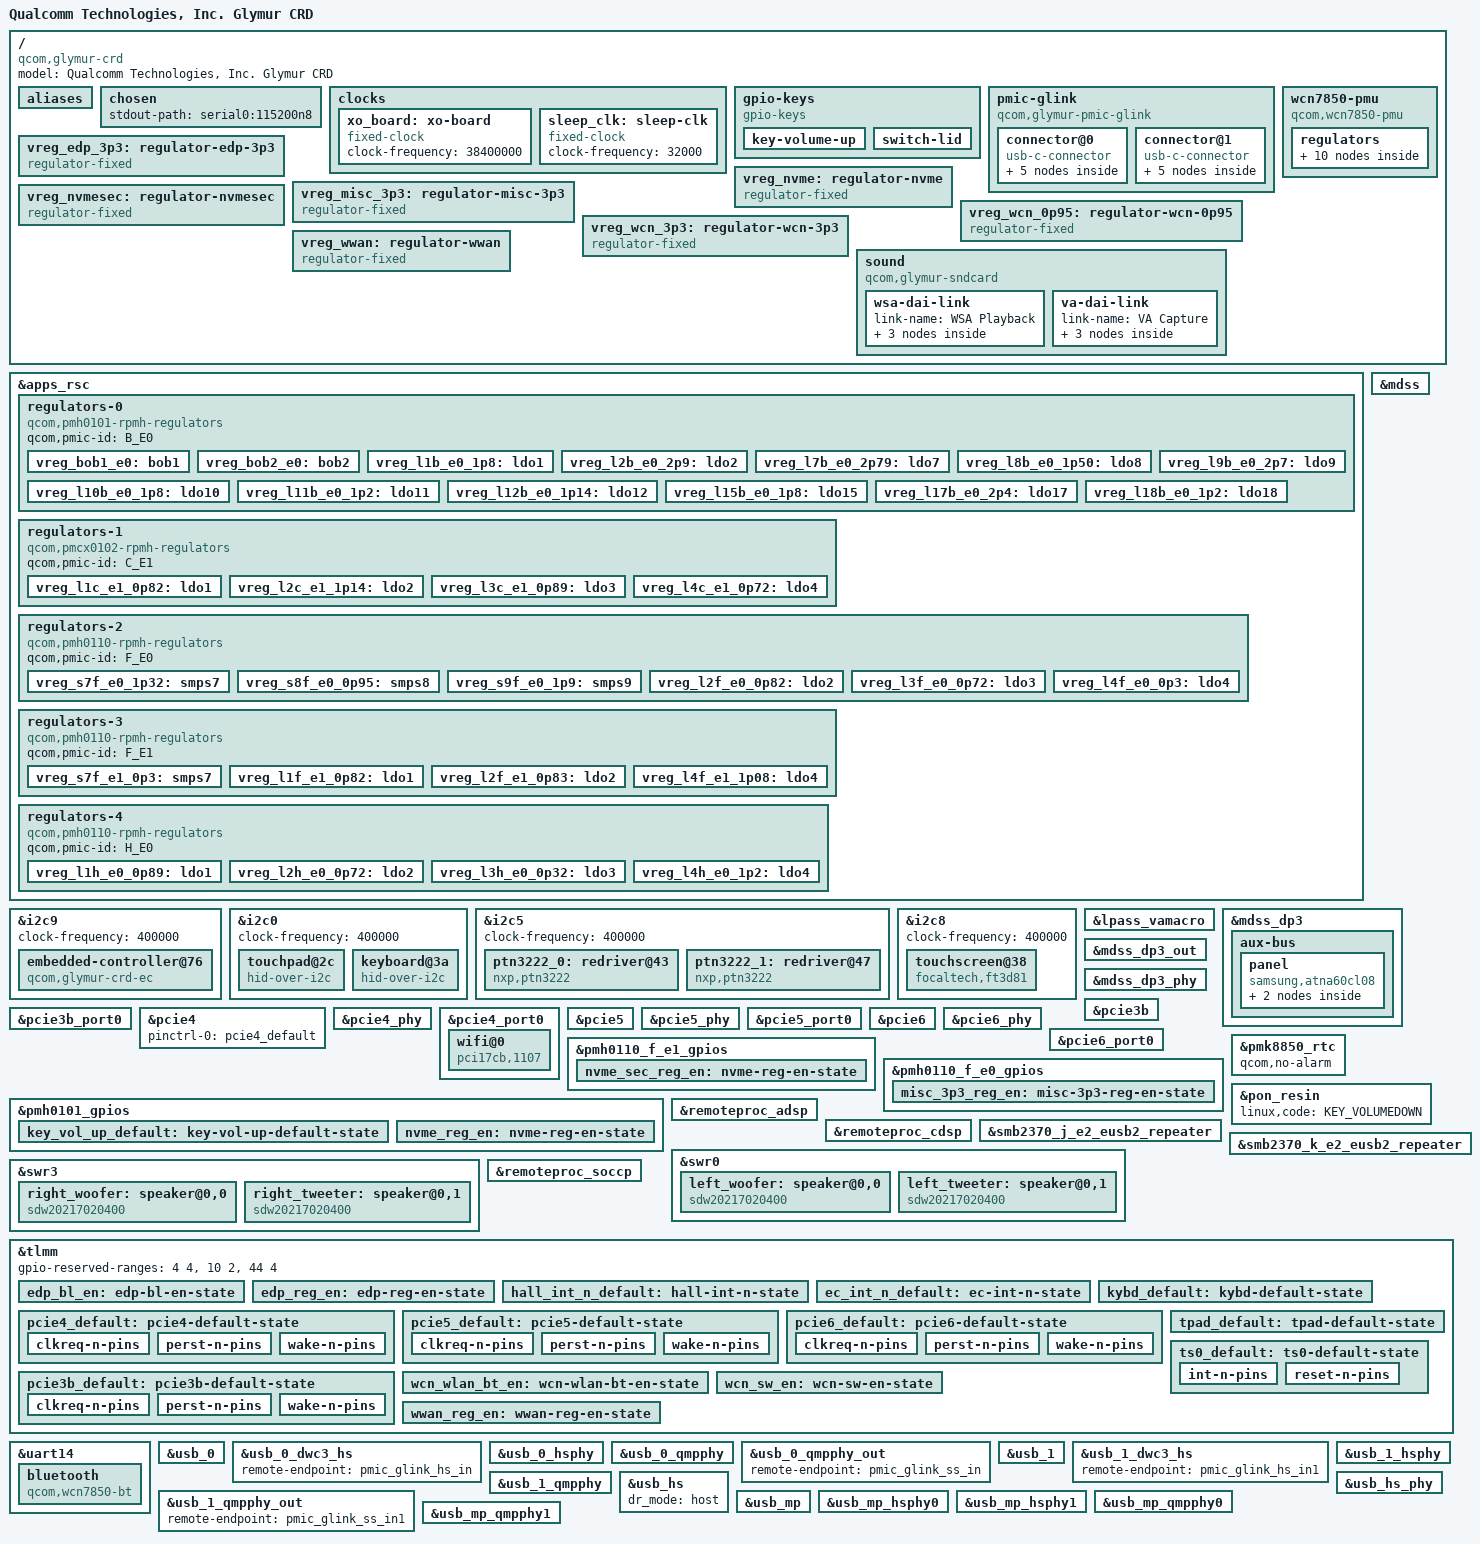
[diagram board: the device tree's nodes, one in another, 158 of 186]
// SPDX-License-Identifier: BSD-3-Clause
/*
 * Copyright (c) Qualcomm Technologies, Inc. and/or its subsidiaries.
 */

#include "pmcx0102.dtsi"        /* SPMI0: SID-2/3 SPMI1: SID-2/3 */
#include "pmh0101.dtsi"         /* SPMI0: SID-1                  */
#include "pmh0110-glymur.dtsi"  /* SPMI0: SID-5/7 SPMI1: SID-5   */
#include "pmh0104-glymur.dtsi"  /* SPMI0: SID-8/9 SPMI1: SID-11  */
#include "pmk8850.dtsi"         /* SPMI0: SID-0                  */
#include "smb2370.dtsi"         /* SPMI2: SID-9/10/11            */

#include <dt-bindings/input/gpio-keys.h>
#include <dt-bindings/pinctrl/qcom,pmic-gpio.h>

/ {
	model = "Qualcomm Technologies, Inc. Glymur CRD";
	compatible = "qcom,glymur-crd", "qcom,glymur";

	aliases {
		serial0 = &uart21;
		serial1 = &uart14;
		i2c0 = &i2c0;
		i2c1 = &i2c4;
		i2c2 = &i2c5;
		i2c3 = &i2c9;
		spi0 = &spi18;
	};

	chosen {
		stdout-path = "serial0:115200n8";
	};

	clocks {
		xo_board: xo-board {
			compatible = "fixed-clock";
			clock-frequency = <38400000>;
			#clock-cells = <0>;
		};

		sleep_clk: sleep-clk {
			compatible = "fixed-clock";
			clock-frequency = <32000>;
			#clock-cells = <0>;
		};
	};

	gpio-keys {
		compatible = "gpio-keys";

		pinctrl-0 = <&key_vol_up_default>, <&hall_int_n_default>;
		pinctrl-names = "default";

		key-volume-up {
			label = "Volume Up";
			linux,code = <KEY_VOLUMEUP>;
			gpios = <&pmh0101_gpios 6 GPIO_ACTIVE_LOW>;
			debounce-interval = <15>;
			linux,can-disable;
			wakeup-source;
		};

		switch-lid {
			label = "lid";
			gpios = <&tlmm 92 GPIO_ACTIVE_LOW>;
			linux,input-type = <EV_SW>;
			linux,code = <SW_LID>;
			wakeup-source;
			wakeup-event-action = <EV_ACT_DEASSERTED>;
		};
	};

	pmic-glink {
		compatible = "qcom,glymur-pmic-glink",
			     "qcom,pmic-glink";
		#address-cells = <1>;
		#size-cells = <0>;

		connector@0 {
			compatible = "usb-c-connector";
			reg = <0>;
			power-role = "dual";
			data-role = "dual";

			ports {
				#address-cells = <1>;
				#size-cells = <0>;

				port@0 {
					reg = <0>;

					pmic_glink_hs_in: endpoint {
						remote-endpoint = <&usb_0_dwc3_hs>;
					};
				};

				port@1 {
					reg = <1>;

					pmic_glink_ss_in: endpoint {
						remote-endpoint = <&usb_0_qmpphy_out>;
					};
				};
			};
		};

		connector@1 {
			compatible = "usb-c-connector";
			reg = <1>;
			power-role = "dual";
			data-role = "dual";

			ports {
				#address-cells = <1>;
				#size-cells = <0>;

				port@0 {
					reg = <0>;

					pmic_glink_hs_in1: endpoint {
						remote-endpoint = <&usb_1_dwc3_hs>;
					};
				};

				port@1 {
					reg = <1>;

					pmic_glink_ss_in1: endpoint {
						remote-endpoint = <&usb_1_qmpphy_out>;
					};
				};
			};
		};
	};

	vreg_edp_3p3: regulator-edp-3p3 {
		compatible = "regulator-fixed";

		regulator-name = "VREG_EDP_3P3";
		regulator-min-microvolt = <3300000>;
		regulator-max-microvolt = <3300000>;

		gpio = <&tlmm 70 GPIO_ACTIVE_HIGH>;
		enable-active-high;

		pinctrl-0 = <&edp_reg_en>;
		pinctrl-names = "default";

		regulator-boot-on;
	};

	vreg_misc_3p3: regulator-misc-3p3 {
		compatible = "regulator-fixed";

		regulator-name = "VREG_MISC_3P3";
		regulator-min-microvolt = <3300000>;
		regulator-max-microvolt = <3300000>;

		gpio = <&pmh0110_f_e0_gpios 6 GPIO_ACTIVE_HIGH>;
		enable-active-high;

		pinctrl-0 = <&misc_3p3_reg_en>;
		pinctrl-names = "default";

		regulator-boot-on;
	};

	vreg_nvme: regulator-nvme {
		compatible = "regulator-fixed";

		regulator-name = "VREG_NVME_3P3";
		regulator-min-microvolt = <3300000>;
		regulator-max-microvolt = <3300000>;

		gpio = <&pmh0101_gpios 14 GPIO_ACTIVE_HIGH>;
		enable-active-high;

		pinctrl-0 = <&nvme_reg_en>;
		pinctrl-names = "default";

		regulator-boot-on;
	};

	vreg_nvmesec: regulator-nvmesec {
		compatible = "regulator-fixed";

		regulator-name = "VREG_NVME_SEC_3P3";
		regulator-min-microvolt = <3300000>;
		regulator-max-microvolt = <3300000>;

		gpio = <&pmh0110_f_e1_gpios 14 GPIO_ACTIVE_HIGH>;
		enable-active-high;

		pinctrl-0 = <&nvme_sec_reg_en>;
		pinctrl-names = "default";

		regulator-boot-on;
	};

	vreg_wcn_0p95: regulator-wcn-0p95 {
		compatible = "regulator-fixed";

		regulator-name = "VREG_WCN_0P95";
		regulator-min-microvolt = <950000>;
		regulator-max-microvolt = <950000>;

		vin-supply = <&vreg_wcn_3p3>;
	};

	vreg_wcn_3p3: regulator-wcn-3p3 {
		compatible = "regulator-fixed";

		regulator-name = "VREG_WCN_3P3";
		regulator-min-microvolt = <3300000>;
		regulator-max-microvolt = <3300000>;

		gpio = <&tlmm 94 GPIO_ACTIVE_HIGH>;
		enable-active-high;

		pinctrl-0 = <&wcn_sw_en>;
		pinctrl-names = "default";

		regulator-boot-on;
	};

	vreg_wwan: regulator-wwan {
		compatible = "regulator-fixed";

		regulator-name = "VREG_WWAN_3P3";
		regulator-min-microvolt = <3300000>;
		regulator-max-microvolt = <3300000>;

		gpio = <&tlmm 246 GPIO_ACTIVE_HIGH>;
		enable-active-high;

		pinctrl-0 = <&wwan_reg_en>;
		pinctrl-names = "default";
	};

	sound {
		compatible = "qcom,glymur-sndcard";
		model = "GLYMUR-CRD";
		audio-routing = "WooferLeft IN", "WSA WSA_SPK1 OUT",
				"TweeterLeft IN", "WSA WSA_SPK2 OUT",
				"WooferRight IN", "WSA2 WSA_SPK1 OUT",
				"TweeterRight IN", "WSA2 WSA_SPK2 OUT",
				"VA DMIC0", "vdd-micb",
				"VA DMIC1", "vdd-micb",
				"VA DMIC2", "vdd-micb",
				"VA DMIC3", "vdd-micb";

		wsa-dai-link {
			link-name = "WSA Playback";

			cpu {
				sound-dai = <&q6apmbedai WSA_CODEC_DMA_RX_0>;
			};

			codec {
				sound-dai = <&left_woofer>, <&left_tweeter>,
					    <&swr0 0>, <&lpass_wsamacro 0>,
					    <&right_woofer>, <&right_tweeter>,
					    <&swr3 0>, <&lpass_wsa2macro 0>;
			};

			platform {
				sound-dai = <&q6apm>;
			};
		};

		va-dai-link {
			link-name = "VA Capture";

			cpu {
				sound-dai = <&q6apmbedai VA_CODEC_DMA_TX_0>;
			};

			codec {
				sound-dai = <&lpass_vamacro 0>;
			};

			platform {
				sound-dai = <&q6apm>;
			};
		};
	};

	wcn7850-pmu {
		compatible = "qcom,wcn7850-pmu";

		vdd-supply = <&vreg_wcn_0p95>;
		vddio-supply = <&vreg_l15b_e0_1p8>;
		vddaon-supply = <&vreg_l15b_e0_1p8>;
		vdddig-supply = <&vreg_l15b_e0_1p8>;
		vddrfa1p2-supply = <&vreg_l15b_e0_1p8>;
		vddrfa1p8-supply = <&vreg_l15b_e0_1p8>;

		wlan-enable-gpios = <&tlmm 117 GPIO_ACTIVE_HIGH>;
		bt-enable-gpios = <&tlmm 116 GPIO_ACTIVE_HIGH>;

		pinctrl-0 = <&wcn_wlan_bt_en>;
		pinctrl-names = "default";

		regulators {
			vreg_pmu_rfa_cmn: ldo0 {
				regulator-name = "vreg_pmu_rfa_cmn";
			};

			vreg_pmu_aon_0p59: ldo1 {
				regulator-name = "vreg_pmu_aon_0p59";
			};

			vreg_pmu_wlcx_0p8: ldo2 {
				regulator-name = "vreg_pmu_wlcx_0p8";
			};

			vreg_pmu_wlmx_0p85: ldo3 {
				regulator-name = "vreg_pmu_wlmx_0p85";
			};

			vreg_pmu_btcmx_0p85: ldo4 {
				regulator-name = "vreg_pmu_btcmx_0p85";
			};

			vreg_pmu_rfa_0p8: ldo5 {
				regulator-name = "vreg_pmu_rfa_0p8";
			};

			vreg_pmu_rfa_1p2: ldo6 {
				regulator-name = "vreg_pmu_rfa_1p2";
			};

			vreg_pmu_rfa_1p8: ldo7 {
				regulator-name = "vreg_pmu_rfa_1p8";
			};

			vreg_pmu_pcie_0p9: ldo8 {
				regulator-name = "vreg_pmu_pcie_0p9";
			};

			vreg_pmu_pcie_1p8: ldo9 {
				regulator-name = "vreg_pmu_pcie_1p8";
			};
		};
	};
};

&apps_rsc {
	regulators-0 {
		compatible = "qcom,pmh0101-rpmh-regulators";
		qcom,pmic-id = "B_E0";

		vreg_bob1_e0: bob1 {
			regulator-name = "vreg_bob1_e0";
			regulator-min-microvolt = <2200000>;
			regulator-max-microvolt = <4224000>;
			regulator-initial-mode = <RPMH_REGULATOR_MODE_AUTO>;
		};

		vreg_bob2_e0: bob2 {
			regulator-name = "vreg_bob2_e0";
			regulator-min-microvolt = <2540000>;
			regulator-max-microvolt = <3600000>;
			regulator-initial-mode = <RPMH_REGULATOR_MODE_AUTO>;
		};

		vreg_l1b_e0_1p8: ldo1 {
			regulator-name = "vreg_l1b_e0_1p8";
			regulator-min-microvolt = <1800000>;
			regulator-max-microvolt = <1800000>;
			regulator-initial-mode = <RPMH_REGULATOR_MODE_HPM>;
		};

		vreg_l2b_e0_2p9: ldo2 {
			regulator-name = "vreg_l2b_e0_2p9";
			regulator-min-microvolt = <2904000>;
			regulator-max-microvolt = <2904000>;
			regulator-initial-mode = <RPMH_REGULATOR_MODE_HPM>;
		};

		vreg_l7b_e0_2p79: ldo7 {
			regulator-name = "vreg_l7b_e0_2p79";
			regulator-min-microvolt = <2790000>;
			regulator-max-microvolt = <2792000>;
			regulator-initial-mode = <RPMH_REGULATOR_MODE_HPM>;
		};

		vreg_l8b_e0_1p50: ldo8 {
			regulator-name = "vreg_l8b_e0_1p50";
			regulator-min-microvolt = <1504000>;
			regulator-max-microvolt = <1504000>;
			regulator-initial-mode = <RPMH_REGULATOR_MODE_HPM>;
		};

		vreg_l9b_e0_2p7: ldo9 {
			regulator-name = "vreg_l9b_e0_2p7";
			regulator-min-microvolt = <2704000>;
			regulator-max-microvolt = <2704000>;
			regulator-initial-mode = <RPMH_REGULATOR_MODE_HPM>;
		};

		vreg_l10b_e0_1p8: ldo10 {
			regulator-name = "vreg_l10b_e0_1p8";
			regulator-min-microvolt = <1800000>;
			regulator-max-microvolt = <1800000>;
			regulator-initial-mode = <RPMH_REGULATOR_MODE_HPM>;
		};

		vreg_l11b_e0_1p2: ldo11 {
			regulator-name = "vreg_l11b_e0_1p2";
			regulator-min-microvolt = <1200000>;
			regulator-max-microvolt = <1200000>;
			regulator-initial-mode = <RPMH_REGULATOR_MODE_HPM>;
		};

		vreg_l12b_e0_1p14: ldo12 {
			regulator-name = "vreg_l12b_e0_1p14";
			regulator-min-microvolt = <1144000>;
			regulator-max-microvolt = <1144000>;
			regulator-initial-mode = <RPMH_REGULATOR_MODE_HPM>;
		};

		vreg_l15b_e0_1p8: ldo15 {
			regulator-name = "vreg_l15b_e0_1p8";
			regulator-min-microvolt = <1800000>;
			regulator-max-microvolt = <1800000>;
			regulator-initial-mode = <RPMH_REGULATOR_MODE_HPM>;
		};

		vreg_l17b_e0_2p4: ldo17 {
			regulator-name = "vreg_l17b_e0_2p4";
			regulator-min-microvolt = <2400000>;
			regulator-max-microvolt = <2700000>;
			regulator-initial-mode = <RPMH_REGULATOR_MODE_HPM>;
		};

		vreg_l18b_e0_1p2: ldo18 {
			regulator-name = "vreg_l18b_e0_1p2";
			regulator-min-microvolt = <1200000>;
			regulator-max-microvolt = <1200000>;
			regulator-initial-mode = <RPMH_REGULATOR_MODE_HPM>;
		};
	};

	regulators-1 {
		compatible = "qcom,pmcx0102-rpmh-regulators";
		qcom,pmic-id = "C_E1";

		vreg_l1c_e1_0p82: ldo1 {
			regulator-name = "vreg_l1c_e1_0p82";
			regulator-min-microvolt = <832000>;
			regulator-max-microvolt = <832000>;
			regulator-initial-mode = <RPMH_REGULATOR_MODE_HPM>;
		};

		vreg_l2c_e1_1p14: ldo2 {
			regulator-name = "vreg_l2c_e1_1p14";
			regulator-min-microvolt = <1144000>;
			regulator-max-microvolt = <1144000>;
			regulator-initial-mode = <RPMH_REGULATOR_MODE_HPM>;
		};

		vreg_l3c_e1_0p89: ldo3 {
			regulator-name = "vreg_l3c_e1_0p89";
			regulator-min-microvolt = <890000>;
			regulator-max-microvolt = <980000>;
			regulator-initial-mode = <RPMH_REGULATOR_MODE_HPM>;
		};

		vreg_l4c_e1_0p72: ldo4 {
			regulator-name = "vreg_l4c_e1_0p72";
			regulator-min-microvolt = <720000>;
			regulator-max-microvolt = <720000>;
			regulator-initial-mode = <RPMH_REGULATOR_MODE_HPM>;
		};
	};

	regulators-2 {
		compatible = "qcom,pmh0110-rpmh-regulators";
		qcom,pmic-id = "F_E0";

		vreg_s7f_e0_1p32: smps7 {
			regulator-name = "vreg_s7f_e0_1p32";
			regulator-min-microvolt = <1320000>;
			regulator-max-microvolt = <1352000>;
			regulator-initial-mode = <RPMH_REGULATOR_MODE_HPM>;
		};

		vreg_s8f_e0_0p95: smps8 {
			regulator-name = "vreg_s8f_e0_0p95";
			regulator-min-microvolt = <952000>;
			regulator-max-microvolt = <1200000>;
			regulator-initial-mode = <RPMH_REGULATOR_MODE_HPM>;
		};

		vreg_s9f_e0_1p9: smps9 {
			regulator-name = "vreg_s9f_e0_1p9";
			regulator-min-microvolt = <1900000>;
			regulator-max-microvolt = <2000000>;
			regulator-initial-mode = <RPMH_REGULATOR_MODE_HPM>;
		};

		vreg_l2f_e0_0p82: ldo2 {
			regulator-name = "vreg_l2f_e0_0p82";
			regulator-min-microvolt = <832000>;
			regulator-max-microvolt = <832000>;
			regulator-initial-mode = <RPMH_REGULATOR_MODE_HPM>;
		};

		vreg_l3f_e0_0p72: ldo3 {
			regulator-name = "vreg_l3f_e0_0p72";
			regulator-min-microvolt = <720000>;
			regulator-max-microvolt = <720000>;
			regulator-initial-mode = <RPMH_REGULATOR_MODE_HPM>;
		};

		vreg_l4f_e0_0p3: ldo4 {
			regulator-name = "vreg_l4f_e0_0p3";
			regulator-min-microvolt = <1080000>;
			regulator-max-microvolt = <1200000>;
			regulator-initial-mode = <RPMH_REGULATOR_MODE_HPM>;
		};
	};

	regulators-3 {
		compatible = "qcom,pmh0110-rpmh-regulators";
		qcom,pmic-id = "F_E1";

		vreg_s7f_e1_0p3: smps7 {
			regulator-name = "vreg_s7f_e1_0p3";
			regulator-min-microvolt = <300000>;
			regulator-max-microvolt = <1200000>;
			regulator-initial-mode = <RPMH_REGULATOR_MODE_HPM>;
		};

		vreg_l1f_e1_0p82: ldo1 {
			regulator-name = "vreg_l1f_e1_0p82";
			regulator-min-microvolt = <832000>;
			regulator-max-microvolt = <832000>;
			regulator-initial-mode = <RPMH_REGULATOR_MODE_HPM>;
		};

		vreg_l2f_e1_0p83: ldo2 {
			regulator-name = "vreg_l2f_e1_0p83";
			regulator-min-microvolt = <832000>;
			regulator-max-microvolt = <832000>;
			regulator-initial-mode = <RPMH_REGULATOR_MODE_HPM>;
		};

		vreg_l4f_e1_1p08: ldo4 {
			regulator-name = "vreg_l4f_e1_1p08";
			regulator-min-microvolt = <1080000>;
			regulator-max-microvolt = <1320000>;
			regulator-initial-mode = <RPMH_REGULATOR_MODE_HPM>;
		};
	};

	regulators-4 {
		compatible = "qcom,pmh0110-rpmh-regulators";
		qcom,pmic-id = "H_E0";

		vreg_l1h_e0_0p89: ldo1 {
			regulator-name = "vreg_l1h_e0_0p89";
			regulator-min-microvolt = <832000>;
			regulator-max-microvolt = <832000>;
			regulator-initial-mode = <RPMH_REGULATOR_MODE_HPM>;
		};

		vreg_l2h_e0_0p72: ldo2 {
			regulator-name = "vreg_l2h_e0_0p72";
			regulator-min-microvolt = <832000>;
			regulator-max-microvolt = <832000>;
			regulator-initial-mode = <RPMH_REGULATOR_MODE_HPM>;
		};

		vreg_l3h_e0_0p32: ldo3 {
			regulator-name = "vreg_l3h_e0_0p32";
			regulator-min-microvolt = <320000>;
			regulator-max-microvolt = <2000000>;
			regulator-initial-mode = <RPMH_REGULATOR_MODE_HPM>;
		};

		vreg_l4h_e0_1p2: ldo4 {
			regulator-name = "vreg_l4h_e0_1p2";
			regulator-min-microvolt = <1080000>;
			regulator-max-microvolt = <1320000>;
			regulator-initial-mode = <RPMH_REGULATOR_MODE_HPM>;
		};
	};
};

&i2c9 {
	clock-frequency = <400000>;

	status = "okay";

	embedded-controller@76 {
		compatible = "qcom,glymur-crd-ec", "qcom,hamoa-crd-ec";
		reg = <0x76>;

		interrupts-extended = <&tlmm 66 IRQ_TYPE_EDGE_FALLING>;

		pinctrl-0 = <&ec_int_n_default>;
		pinctrl-names = "default";
	};
};

&i2c0 {
	clock-frequency = <400000>;

	status = "okay";

	touchpad@2c {
		compatible = "hid-over-i2c";
		reg = <0x2c>;

		hid-descr-addr = <0x20>;
		interrupts-extended = <&tlmm 3 IRQ_TYPE_LEVEL_LOW>;

		vdd-supply = <&vreg_misc_3p3>;
		vddl-supply = <&vreg_l15b_e0_1p8>;

		pinctrl-0 = <&tpad_default>;
		pinctrl-names = "default";

		wakeup-source;
	};

	keyboard@3a {
		compatible = "hid-over-i2c";
		reg = <0x3a>;

		hid-descr-addr = <0x1>;
		interrupts-extended = <&tlmm 67 IRQ_TYPE_LEVEL_LOW>;

		vdd-supply = <&vreg_misc_3p3>;
		vddl-supply = <&vreg_l15b_e0_1p8>;

		pinctrl-0 = <&kybd_default>;
		pinctrl-names = "default";

		wakeup-source;
	};
};

&i2c5 {
	clock-frequency = <400000>;

	status = "okay";

	ptn3222_0: redriver@43 {
		compatible = "nxp,ptn3222";
		reg = <0x43>;

		reset-gpios = <&tlmm 8 GPIO_ACTIVE_LOW>;

		vdd3v3-supply = <&vreg_l8b_e0_1p50>;
		vdd1v8-supply = <&vreg_l15b_e0_1p8>;

		#phy-cells = <0>;
	};

	ptn3222_1: redriver@47 {
		compatible = "nxp,ptn3222";
		reg = <0x47>;

		reset-gpios = <&tlmm 9 GPIO_ACTIVE_LOW>;

		vdd3v3-supply = <&vreg_l8b_e0_1p50>;
		vdd1v8-supply = <&vreg_l15b_e0_1p8>;

		#phy-cells = <0>;
	};
};

&i2c8 {
	clock-frequency = <400000>;

	status = "okay";

	touchscreen@38 {
		compatible = "focaltech,ft3d81", "focaltech,ft8112";
		reg = <0x38>;

		interrupts-extended = <&tlmm 51 IRQ_TYPE_LEVEL_LOW>;

		vcc33-supply = <&vreg_misc_3p3>;
		vccio-supply = <&vreg_l15b_e0_1p8>;

		reset-gpios = <&tlmm 48 GPIO_ACTIVE_LOW>;

		pinctrl-0 = <&ts0_default>;
		pinctrl-names = "default";
	};
};

&lpass_vamacro {
	pinctrl-0 = <&dmic01_default>, <&dmic23_default>;
	pinctrl-names = "default";
	qcom,dmic-sample-rate = <4800000>;
	vdd-micb-supply = <&vreg_l1b_e0_1p8>;
};

&mdss {
	status = "okay";
};

&mdss_dp3 {
	/delete-property/ #sound-dai-cells;

	status = "okay";

	aux-bus {
		panel {
			compatible = "samsung,atna60cl08", "samsung,atna33xc20";
			enable-gpios = <&tlmm 18 GPIO_ACTIVE_HIGH>;
			power-supply = <&vreg_edp_3p3>;

			pinctrl-0 = <&edp_bl_en>;
			pinctrl-names = "default";

			port {
				edp_panel_in: endpoint {
					remote-endpoint = <&mdss_dp3_out>;
				};
			};
		};
	};
};

&mdss_dp3_out {
	data-lanes = <0 1 2 3>;
	link-frequencies = /bits/ 64 <1620000000 2700000000 5400000000 8100000000>;

	remote-endpoint = <&edp_panel_in>;
};

&mdss_dp3_phy {
	vdda-phy-supply = <&vreg_l2f_e1_0p83>;
	vdda-pll-supply = <&vreg_l4f_e1_1p08>;

	status = "okay";
};

&pcie3b {
	vddpe-3v3-supply = <&vreg_nvmesec>;

	pinctrl-0 = <&pcie3b_default>;
	pinctrl-names = "default";
};

&pcie3b_port0 {
	reset-gpios = <&tlmm 155 GPIO_ACTIVE_LOW>;
	wake-gpios = <&tlmm 157 GPIO_ACTIVE_LOW>;
};

&pcie4 {
	pinctrl-0 = <&pcie4_default>;
	pinctrl-names = "default";

	status = "okay";
};

&pcie4_phy {
	vdda-phy-supply = <&vreg_l1c_e1_0p82>;
	vdda-pll-supply = <&vreg_l4f_e1_1p08>;

	status = "okay";
};

&pcie4_port0 {
	reset-gpios = <&tlmm 146 GPIO_ACTIVE_LOW>;
	wake-gpios = <&tlmm 148 GPIO_ACTIVE_LOW>;

	wifi@0 {
		compatible = "pci17cb,1107";
		reg = <0x10000 0x0 0x0 0x0 0x0>;

		vddaon-supply = <&vreg_pmu_aon_0p59>;
		vddwlcx-supply = <&vreg_pmu_wlcx_0p8>;
		vddwlmx-supply = <&vreg_pmu_wlmx_0p85>;
		vddrfacmn-supply = <&vreg_pmu_rfa_cmn>;
		vddrfa0p8-supply = <&vreg_pmu_rfa_0p8>;
		vddrfa1p2-supply = <&vreg_pmu_rfa_1p2>;
		vddrfa1p8-supply = <&vreg_pmu_rfa_1p8>;
		vddpcie0p9-supply = <&vreg_pmu_pcie_0p9>;
		vddpcie1p8-supply = <&vreg_pmu_pcie_1p8>;
	};
};

&pcie5 {
	vddpe-3v3-supply = <&vreg_nvme>;

	pinctrl-0 = <&pcie5_default>;
	pinctrl-names = "default";

	status = "okay";
};

&pcie5_phy {
	vdda-phy-supply = <&vreg_l2f_e0_0p82>;
	vdda-pll-supply = <&vreg_l4h_e0_1p2>;

	status = "okay";
};

&pcie5_port0 {
	reset-gpios = <&tlmm 152 GPIO_ACTIVE_LOW>;
	wake-gpios = <&tlmm 154 GPIO_ACTIVE_LOW>;
};

&pcie6 {
	vddpe-3v3-supply = <&vreg_wwan>;

	pinctrl-0 = <&pcie6_default>;
	pinctrl-names = "default";

	status = "okay";
};

&pcie6_phy {
	vdda-phy-supply = <&vreg_l1c_e1_0p82>;
	vdda-pll-supply = <&vreg_l4f_e1_1p08>;

	status = "okay";
};

&pcie6_port0 {
	reset-gpios = <&tlmm 149 GPIO_ACTIVE_LOW>;
	wake-gpios = <&tlmm 151 GPIO_ACTIVE_LOW>;
};

&pmh0110_f_e1_gpios {
	nvme_sec_reg_en: nvme-reg-en-state {
		pins = "gpio14";
		function = "normal";
		bias-disable;
	};
};

&pmh0101_gpios {
	key_vol_up_default: key-vol-up-default-state {
		pins = "gpio6";
		function = "normal";
		output-disable;
		bias-pull-up;
	};

	nvme_reg_en: nvme-reg-en-state {
		pins = "gpio14";
		function = "normal";
		bias-disable;
	};
};

&pmh0110_f_e0_gpios {
	misc_3p3_reg_en: misc-3p3-reg-en-state {
		pins = "gpio6";
		function = "normal";
		bias-disable;
		input-disable;
		output-enable;
		drive-push-pull;
		power-source = <1>; /* 1.8 V */
		qcom,drive-strength = <PMIC_GPIO_STRENGTH_LOW>;
	};
};

&pmk8850_rtc {
	qcom,no-alarm;
};

&pon_resin {
	linux,code = <KEY_VOLUMEDOWN>;
	status = "okay";
};

&remoteproc_adsp {
	firmware-name = "qcom/glymur/adsp.mbn",
			"qcom/glymur/adsp_dtb.mbn";

	status = "okay";
};

&remoteproc_cdsp {
	firmware-name = "qcom/glymur/cdsp.mbn",
			"qcom/glymur/cdsp_dtb.mbn";

	status = "okay";
};

&smb2370_j_e2_eusb2_repeater {
	vdd18-supply = <&vreg_l15b_e0_1p8>;
	vdd3-supply = <&vreg_l7b_e0_2p79>;
};

&smb2370_k_e2_eusb2_repeater {
	vdd18-supply = <&vreg_l15b_e0_1p8>;
	vdd3-supply = <&vreg_l7b_e0_2p79>;
};

&swr0 {
	status = "okay";

	/* WSA8845, Left Woofer */
	left_woofer: speaker@0,0 {
		compatible = "sdw20217020400";
		reg = <0 0>;
		reset-gpios = <&lpass_tlmm 12 GPIO_ACTIVE_LOW>;
		#sound-dai-cells = <0>;
		sound-name-prefix = "WooferLeft";
		vdd-1p8-supply = <&vreg_l15b_e0_1p8>;
		vdd-io-supply = <&vreg_l18b_e0_1p2>;
		qcom,port-mapping = <1 2 3 7 12 14>;
	};

	/* WSA8845, Left Tweeter */
	left_tweeter: speaker@0,1 {
		compatible = "sdw20217020400";
		reg = <0 1>;
		reset-gpios = <&lpass_tlmm 12 GPIO_ACTIVE_LOW>;
		#sound-dai-cells = <0>;
		sound-name-prefix = "TweeterLeft";
		vdd-1p8-supply = <&vreg_l15b_e0_1p8>;
		vdd-io-supply = <&vreg_l18b_e0_1p2>;
		qcom,port-mapping = <4 5 6 7 13 15>;
	};
};

&swr3 {
	status = "okay";

	/* WSA8845, Right Woofer */
	right_woofer: speaker@0,0 {
		compatible = "sdw20217020400";
		reg = <0 0>;
		reset-gpios = <&lpass_tlmm 13 GPIO_ACTIVE_LOW>;
		#sound-dai-cells = <0>;
		sound-name-prefix = "WooferRight";
		vdd-1p8-supply = <&vreg_l15b_e0_1p8>;
		vdd-io-supply = <&vreg_l18b_e0_1p2>;
		qcom,port-mapping = <1 2 3 7 12 14>;
	};

	/* WSA8845, Right Tweeter */
	right_tweeter: speaker@0,1 {
		compatible = "sdw20217020400";
		reg = <0 1>;
		reset-gpios = <&lpass_tlmm 13 GPIO_ACTIVE_LOW>;
		#sound-dai-cells = <0>;
		sound-name-prefix = "TweeterRight";
		vdd-1p8-supply = <&vreg_l15b_e0_1p8>;
		vdd-io-supply = <&vreg_l18b_e0_1p2>;
		qcom,port-mapping = <4 5 6 7 13 15>;
	};
};

&remoteproc_soccp {
	firmware-name = "qcom/glymur/soccp.mbn",
			"qcom/glymur/soccp_dtb.mbn";
};

&tlmm {
	gpio-reserved-ranges = <4 4>, /* EC TZ Secure I3C */
			       <10 2>, /* OOB UART */
			       <44 4>; /* Security SPI (TPM) */

	edp_bl_en: edp-bl-en-state {
		pins = "gpio18";
		function = "gpio";
		drive-strength = <16>;
		bias-disable;
	};

	edp_reg_en: edp-reg-en-state {
		pins = "gpio70";
		function = "gpio";
		drive-strength = <16>;
		bias-disable;
	};

	hall_int_n_default: hall-int-n-state {
		pins = "gpio92";
		function = "gpio";
		bias-disable;
	};

	ec_int_n_default: ec-int-n-state {
		pins = "gpio66";
		function = "gpio";
		bias-disable;
	};

	kybd_default: kybd-default-state {
		pins = "gpio67";
		function = "gpio";
		bias-disable;
	};

	pcie4_default: pcie4-default-state {
		clkreq-n-pins {
			pins = "gpio147";
			function = "pcie4_clk_req_n";
			drive-strength = <2>;
			bias-pull-up;
		};

		perst-n-pins {
			pins = "gpio146";
			function = "gpio";
			drive-strength = <2>;
			bias-disable;
		};

		wake-n-pins {
			pins = "gpio148";
			function = "gpio";
			drive-strength = <2>;
			bias-pull-up;
		};
	};

	pcie5_default: pcie5-default-state {
		clkreq-n-pins {
			pins = "gpio153";
			function = "pcie5_clk_req_n";
			drive-strength = <2>;
			bias-pull-up;
		};

		perst-n-pins {
			pins = "gpio152";
			function = "gpio";
			drive-strength = <2>;
			bias-disable;
		};

		wake-n-pins {
			pins = "gpio154";
			function = "gpio";
			drive-strength = <2>;
			bias-pull-up;
		};
	};

	pcie6_default: pcie6-default-state {
		clkreq-n-pins {
			pins = "gpio150";
			function = "pcie6_clk_req_n";
			drive-strength = <2>;
			bias-pull-up;
		};

		perst-n-pins {
			pins = "gpio149";
			function = "gpio";
			drive-strength = <2>;
			bias-disable;
		};

		wake-n-pins {
			pins = "gpio151";
			function = "gpio";
			drive-strength = <2>;
			bias-pull-up;
		};
	};

	pcie3b_default: pcie3b-default-state {
		clkreq-n-pins {
			pins = "gpio156";
			function = "pcie3b_clk";
			drive-strength = <2>;
			bias-pull-up;
		};

		perst-n-pins {
			pins = "gpio155";
			function = "gpio";
			drive-strength = <2>;
			bias-disable;
		};

		wake-n-pins {
			pins = "gpio157";
			function = "gpio";
			drive-strength = <2>;
			bias-pull-up;
		};
	};

	tpad_default: tpad-default-state {
		pins = "gpio3";
		function = "gpio";
		bias-disable;
	};

	ts0_default: ts0-default-state {
		int-n-pins {
			pins = "gpio51";
			function = "gpio";
			bias-disable;
		};

		reset-n-pins {
			pins = "gpio48";
			function = "gpio";
			drive-strength = <16>;
			bias-disable;
		};
	};

	wcn_wlan_bt_en: wcn-wlan-bt-en-state {
		pins = "gpio116", "gpio117";
		function = "gpio";
		drive-strength = <2>;
		bias-disable;
	};

	wcn_sw_en: wcn-sw-en-state {
		pins = "gpio94";
		function = "gpio";
		drive-strength = <2>;
		bias-disable;
	};

	wwan_reg_en: wwan-reg-en-state {
		pins = "gpio246";
		function = "gpio";
		drive-strength = <2>;
		bias-disable;
	};
};

&uart14 {
	status = "okay";

	bluetooth {
		compatible = "qcom,wcn7850-bt";
		max-speed = <3200000>;

		vddaon-supply = <&vreg_pmu_aon_0p59>;
		vddwlcx-supply = <&vreg_pmu_wlcx_0p8>;
		vddwlmx-supply = <&vreg_pmu_wlmx_0p85>;
		vddrfacmn-supply = <&vreg_pmu_rfa_cmn>;
		vddrfa0p8-supply = <&vreg_pmu_rfa_0p8>;
		vddrfa1p2-supply = <&vreg_pmu_rfa_1p2>;
		vddrfa1p8-supply = <&vreg_pmu_rfa_1p8>;
	};
};

&usb_0 {
	status = "okay";
};

&usb_0_dwc3_hs {
	remote-endpoint = <&pmic_glink_hs_in>;
};

&usb_0_hsphy {
	vdd-supply = <&vreg_l3f_e0_0p72>;
	vdda12-supply = <&vreg_l4h_e0_1p2>;

	phys = <&smb2370_j_e2_eusb2_repeater>;

	status = "okay";
};

&usb_0_qmpphy {
	vdda-phy-supply = <&vreg_l3f_e0_0p72>;
	vdda-pll-supply = <&vreg_l4h_e0_1p2>;
	refgen-supply = <&vreg_l2f_e0_0p82>;

	status = "okay";
};

&usb_0_qmpphy_out {
	remote-endpoint = <&pmic_glink_ss_in>;
};

&usb_1 {
	status = "okay";
};

&usb_1_dwc3_hs {
	remote-endpoint = <&pmic_glink_hs_in1>;
};

&usb_1_hsphy {
	vdd-supply = <&vreg_l3f_e0_0p72>;
	vdda12-supply = <&vreg_l4h_e0_1p2>;

	phys = <&smb2370_k_e2_eusb2_repeater>;

	status = "okay";
};

&usb_1_qmpphy {
	vdda-phy-supply = <&vreg_l1h_e0_0p89>;
	vdda-pll-supply = <&vreg_l4h_e0_1p2>;
	refgen-supply = <&vreg_l2f_e0_0p82>;

	status = "okay";
};

&usb_1_qmpphy_out {
	remote-endpoint = <&pmic_glink_ss_in1>;
};

&usb_hs {
	dr_mode = "host";

	status = "okay";
};

&usb_hs_phy {
	vdd-supply = <&vreg_l2h_e0_0p72>;
	vdda12-supply = <&vreg_l4h_e0_1p2>;

	phys = <&ptn3222_1>;

	status = "okay";
};

&usb_mp {
	status = "okay";
};

&usb_mp_hsphy0 {
	vdd-supply = <&vreg_l2h_e0_0p72>;
	vdda12-supply = <&vreg_l4h_e0_1p2>;

	phys = <&ptn3222_0>;

	status = "okay";
};

&usb_mp_hsphy1 {
	vdd-supply = <&vreg_l2h_e0_0p72>;
	vdda12-supply = <&vreg_l4h_e0_1p2>;

	status = "okay";
};

&usb_mp_qmpphy0 {
	vdda-phy-supply = <&vreg_l2h_e0_0p72>;
	vdda-pll-supply = <&vreg_l4h_e0_1p2>;
	refgen-supply = <&vreg_l4f_e1_1p08>;

	status = "okay";
};

&usb_mp_qmpphy1 {
	vdda-phy-supply = <&vreg_l2h_e0_0p72>;
	vdda-pll-supply = <&vreg_l4h_e0_1p2>;
	refgen-supply = <&vreg_l4f_e1_1p08>;

	status = "okay";
};
